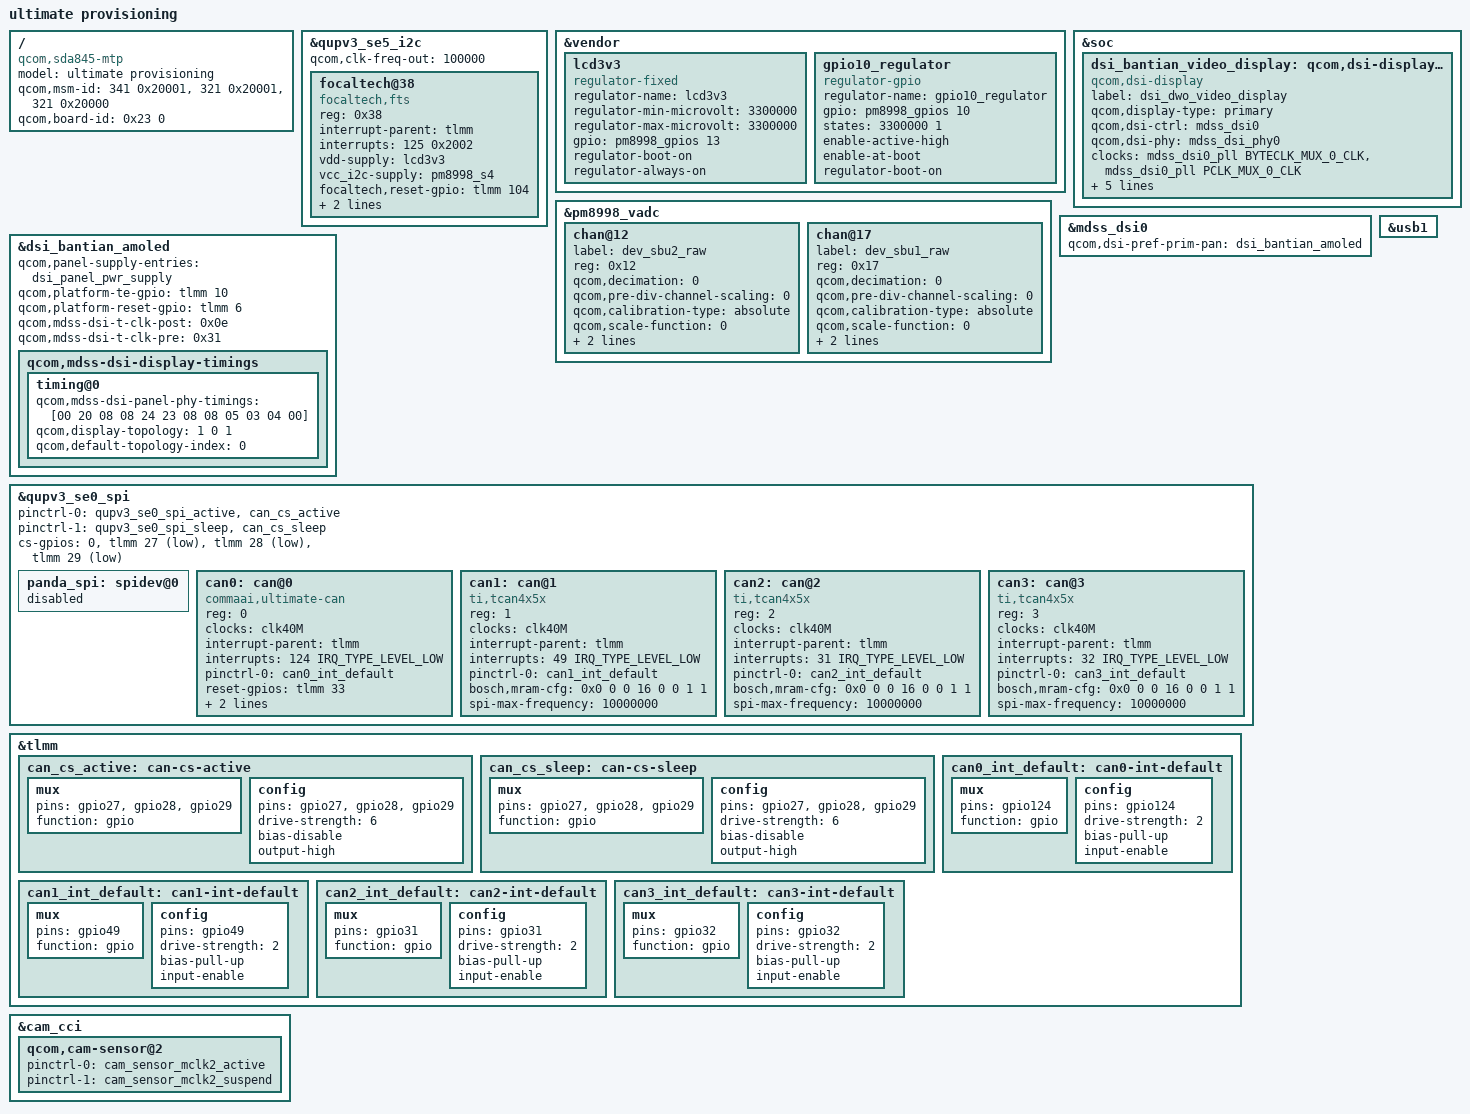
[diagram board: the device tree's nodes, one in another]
/* Copyright (c) 2017, The Linux Foundation. All rights reserved.
 *
 * This program is free software; you can redistribute it and/or modify
 * it under the terms of the GNU General Public License version 2 and
 * only version 2 as published by the Free Software Foundation.
 *
 * This program is distributed in the hope that it will be useful,
 * but WITHOUT ANY WARRANTY; without even the implied warranty of
 * MERCHANTABILITY or FITNESS FOR A PARTICULAR PURPOSE.  See the
 * GNU General Public License for more details.
 */


/dts-v1/;

#include "sda845-v2.1.dtsi"
#include "comma_common.dtsi"
#include "dsi-panel-bantian.dtsi"

/* touch panel I2C, /dev/i2c-2 */
&qupv3_se5_i2c {
  status = "ok";
  qcom,clk-freq-out = <100000>;

  focaltech@38{
    compatible = "focaltech,fts";
    reg = <0x38>;
    interrupt-parent = <&tlmm>;
    interrupts = <125 0x2002>;
    vdd-supply = <&lcd3v3>;
    vcc_i2c-supply = <&pm8998_s4>;
    focaltech,reset-gpio = <&tlmm 104 0>;
    focaltech,irq-gpio = <&tlmm 125 0x2002>;
    focaltech,display-coords = <0 0 240 536>;
  };
};

&vendor {
  lcd3v3: lcd3v3 {
    status = "ok";

    compatible = "regulator-fixed";
    regulator-name = "lcd3v3";
    regulator-min-microvolt = <3300000>;
    regulator-max-microvolt = <3300000>;

    gpio = <&pm8998_gpios 13 0>;
    regulator-boot-on;
    regulator-always-on;
  };

  gpio10_regulator: gpio10_regulator {
    status = "ok";

    compatible = "regulator-gpio";
    regulator-name = "gpio10_regulator";

    gpio = <&pm8998_gpios 10 0>;
    states = <3300000 1>;
    enable-active-high;
    enable-at-boot;
    regulator-boot-on;
  };
};

&pm8998_vadc {
    chan@12 {
        label = "dev_sbu2_raw";
        reg = <0x12>;
        qcom,decimation = <0>;
        qcom,pre-div-channel-scaling = <0>;
        qcom,calibration-type = "absolute";
        qcom,scale-function = <0>;
        qcom,hw-settle-time = <0>;
        qcom,fast-avg-setup = <0>;
    };
    chan@17 {
        label = "dev_sbu1_raw";
        reg = <0x17>;
        qcom,decimation = <0>;
        qcom,pre-div-channel-scaling = <0>;
        qcom,calibration-type = "absolute";
        qcom,scale-function = <0>;
        qcom,hw-settle-time = <0>;
        qcom,fast-avg-setup = <0>;
    };
};

&soc {
  dsi_bantian_video_display: qcom,dsi-display@0 {
    compatible = "qcom,dsi-display";
    label = "dsi_dwo_video_display";
    qcom,display-type = "primary";

    qcom,dsi-ctrl = <&mdss_dsi0>;
    qcom,dsi-phy = <&mdss_dsi_phy0>;
    clocks = <&mdss_dsi0_pll BYTECLK_MUX_0_CLK>, <&mdss_dsi0_pll PCLK_MUX_0_CLK>;
  clock-names = "src_byte_clk", "src_pixel_clk";

    pinctrl-names = "panel_active", "panel_suspend";
    //pinctrl-0 = <&sde_dsi_active &sde_te_active &lcd_3v3_en_n_active &tp_3v3_en_n_active>;
    //pinctrl-1 = <&sde_dsi_suspend &sde_te_suspend &lcd_3v3_en_n_suspend &tp_3v3_en_n_suspend>;
    pinctrl-0 = <&sde_dsi_active &sde_te_active>;
    pinctrl-1 = <&sde_dsi_suspend &sde_te_suspend>;

    qcom,dsi-panel = <&dsi_bantian_amoled>;
    vddio-supply = <&pm8998_l14>;
    vddcore-supply = <&lcd3v3>;

    /*vci-supply = <&disp_vci_vreg>;*/
  };
};

&mdss_dsi0 {
  status = "ok";
    qcom,dsi-pref-prim-pan = <&dsi_bantian_amoled>;
  };

  &dsi_bantian_amoled {
    qcom,panel-supply-entries = <&dsi_panel_pwr_supply>;

    /* gpios are correct and connected */
    qcom,platform-te-gpio = <&tlmm 10 0>;
    qcom,platform-reset-gpio = <&tlmm 6 0>;
    //qcom,panel-errfg-gpio = <&tlmm 135 0>

    qcom,mdss-dsi-t-clk-post = <0x0e>;
    qcom,mdss-dsi-t-clk-pre = <0x31>;
    qcom,mdss-dsi-display-timings {
      timing@0{
        qcom,mdss-dsi-panel-phy-timings = [00 20 08 08 24 23 08 08 05 03 04 00];
        qcom,display-topology = <1 0 1>;
        qcom,default-topology-index = <0>;
      };
    };
  };

&qupv3_se0_spi {
  status = "ok";
  pinctrl-names = "default", "sleep";
  pinctrl-0 = <&qupv3_se0_spi_active &can_cs_active>;
  pinctrl-1 = <&qupv3_se0_spi_sleep &can_cs_sleep>;
  cs-gpios = <0>,
             <&tlmm 27 GPIO_ACTIVE_LOW>,
             <&tlmm 28 GPIO_ACTIVE_LOW>,
             <&tlmm 29 GPIO_ACTIVE_LOW>;

  panda_spi: spidev@0 {
    status = "disabled";
  };

  can0: can@0 {
    compatible = "commaai,ultimate-can";
    status = "okay";
    reg = <0>;
    clocks = <&clk40M>;
    clock-names = "cclk";
    interrupt-parent = <&tlmm>;
    interrupts = <124 IRQ_TYPE_LEVEL_LOW>;
    pinctrl-names = "default";
    pinctrl-0 = <&can0_int_default>;
    reset-gpios = <&tlmm 33 GPIO_ACTIVE_HIGH>;
    bosch,mram-cfg = <0x0 0 0 16 0 0 1 1>;
    spi-max-frequency = <10000000>;
  };

  can1: can@1 {
    compatible = "ti,tcan4x5x";
    status = "okay";
    reg = <1>;
    clocks = <&clk40M>;
    clock-names = "cclk";
    interrupt-parent = <&tlmm>;
    interrupts = <49 IRQ_TYPE_LEVEL_LOW>;
    pinctrl-names = "default";
    pinctrl-0 = <&can1_int_default>;
    bosch,mram-cfg = <0x0 0 0 16 0 0 1 1>;
    spi-max-frequency = <10000000>;
  };

  can2: can@2 {
    compatible = "ti,tcan4x5x";
    status = "okay";
    reg = <2>;
    clocks = <&clk40M>;
    clock-names = "cclk";
    interrupt-parent = <&tlmm>;
    interrupts = <31 IRQ_TYPE_LEVEL_LOW>;
    pinctrl-names = "default";
    pinctrl-0 = <&can2_int_default>;
    bosch,mram-cfg = <0x0 0 0 16 0 0 1 1>;
    spi-max-frequency = <10000000>;
  };

  can3: can@3 {
    compatible = "ti,tcan4x5x";
    status = "okay";
    reg = <3>;
    clocks = <&clk40M>;
    clock-names = "cclk";
    interrupt-parent = <&tlmm>;
    interrupts = <32 IRQ_TYPE_LEVEL_LOW>;
    pinctrl-names = "default";
    pinctrl-0 = <&can3_int_default>;
    bosch,mram-cfg = <0x0 0 0 16 0 0 1 1>;
    spi-max-frequency = <10000000>;
  };
};

&tlmm {
  can_cs_active: can-cs-active {
    mux {
      pins = "gpio27", "gpio28", "gpio29";
      function = "gpio";
    };

    config {
      pins = "gpio27", "gpio28", "gpio29";
      drive-strength = <6>;
      bias-disable;
      output-high;
    };
  };

  can_cs_sleep: can-cs-sleep {
    mux {
      pins = "gpio27", "gpio28", "gpio29";
      function = "gpio";
    };

    config {
      pins = "gpio27", "gpio28", "gpio29";
      drive-strength = <6>;
      bias-disable;
      output-high;
    };
  };

  can0_int_default: can0-int-default {
    mux {
      pins = "gpio124";
      function = "gpio";
    };

    config {
      pins = "gpio124";
      drive-strength = <2>;
      bias-pull-up;
      input-enable;
    };
  };

  can1_int_default: can1-int-default {
    mux {
      pins = "gpio49";
      function = "gpio";
    };

    config {
      pins = "gpio49";
      drive-strength = <2>;
      bias-pull-up;
      input-enable;
    };
  };

  can2_int_default: can2-int-default {
    mux {
      pins = "gpio31";
      function = "gpio";
    };

    config {
      pins = "gpio31";
      drive-strength = <2>;
      bias-pull-up;
      input-enable;
    };
  };

  can3_int_default: can3-int-default {
    mux {
      pins = "gpio32";
      function = "gpio";
    };

    config {
      pins = "gpio32";
      drive-strength = <2>;
      bias-pull-up;
      input-enable;
    };
  };
};

&usb1 {
  /delete-property/ pinctrl-names;
  /delete-property/ pinctrl-0;
  /delete-property/ pinctrl-1;
};

&cam_cci {
  qcom,cam-sensor@2 {
    pinctrl-0 = <&cam_sensor_mclk2_active>;
    pinctrl-1 = <&cam_sensor_mclk2_suspend>;
  };
};

/* Board definition */
/ {
  model = "ultimate provisioning";
  compatible = "qcom,sda845-mtp", "qcom,sda845", "qcom,mtp";
  qcom,msm-id = <341 0x20001>, <321 0x20001>, <321 0x20000>;
  qcom,board-id = <0x23 0>;
};
